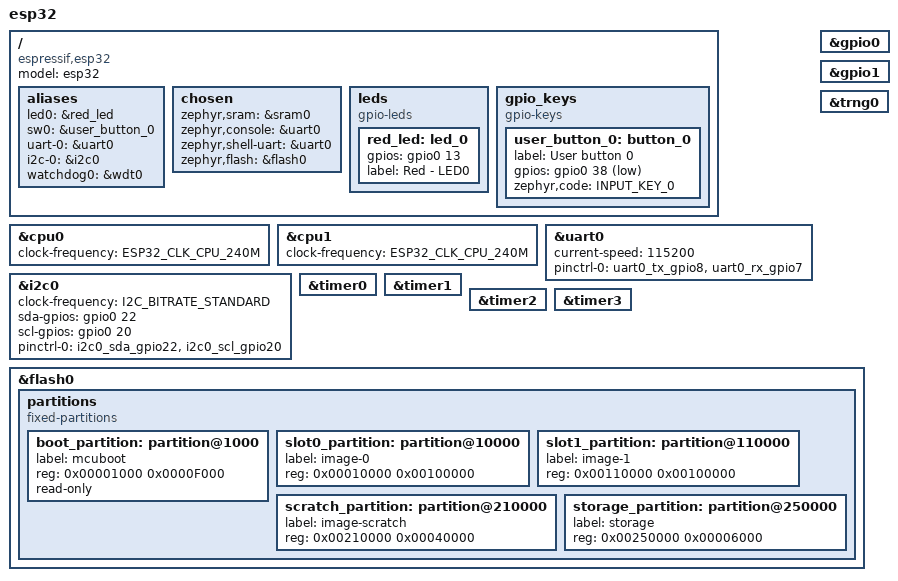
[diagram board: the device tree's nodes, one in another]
/*
 * Copyright (c) 2023 MIT Media Lab
 *
 * SPDX-License-Identifier: Apache-2.0
 */
/dts-v1/;

#include <espressif/esp32/esp32_pico_v3_02.dtsi>
#include "adafruit_feather_esp32_v2-pinctrl.dtsi"
#include <zephyr/dt-bindings/input/input-event-codes.h>

/ {
	model = "esp32";
	compatible = "espressif,esp32";

	aliases {
		led0 = &red_led;
		sw0 = &user_button_0;
		uart-0 = &uart0;
		i2c-0 = &i2c0;
		watchdog0 = &wdt0;
	};

	chosen {
		zephyr,sram = &sram0;
		zephyr,console = &uart0;
		zephyr,shell-uart = &uart0;
		zephyr,flash = &flash0;
	};

	leds {
		compatible = "gpio-leds";

		red_led: led_0 {
			gpios =  <&gpio0 13 GPIO_ACTIVE_HIGH>;
			label = "Red - LED0";
		};
	};

	gpio_keys {
		compatible = "gpio-keys";

		user_button_0: button_0 {
			label = "User button 0";
			gpios = <&gpio0 38 GPIO_ACTIVE_LOW>;
			zephyr,code = <INPUT_KEY_0>;
		};
	};
};

&cpu0 {
	clock-frequency = <ESP32_CLK_CPU_240M>;
};

&cpu1 {
	clock-frequency = <ESP32_CLK_CPU_240M>;
};

&uart0 {
	status = "okay";
	current-speed = <115200>;
	pinctrl-0 = <&uart0_tx_gpio8 &uart0_rx_gpio7>;
	pinctrl-names = "default";
};

&gpio0 {
	status = "okay";
};

&gpio1 {
	status = "okay";
};

&i2c0 {
	status = "okay";
	clock-frequency = <I2C_BITRATE_STANDARD>;
	sda-gpios = <&gpio0 22 GPIO_OPEN_DRAIN>;
	scl-gpios = <&gpio0 20 GPIO_OPEN_DRAIN>;
	pinctrl-0 = <&i2c0_sda_gpio22 &i2c0_scl_gpio20>;
	pinctrl-names = "default";
};

/*
&spi1 {
	#address-cells = <1>;
	#size-cells = <0>;
	status = "okay";
	pinctrl-0 = <&spim2_miso_gpio21 &spim2_mosi_gpio19
				&spim2_sclk_gpio5 &spim2_csel_gpio16>;
	pinctrl-names = "default";
};
*/

&timer0 {
	status = "okay";
};

&timer1 {
	status = "okay";
};

&timer2 {
	status = "okay";
};

&timer3 {
	status = "okay";
};

&trng0 {
	status = "okay";
};

&flash0 {
	status = "okay";
	partitions {
		compatible = "fixed-partitions";
		#address-cells = <1>;
		#size-cells = <1>;

		/* Reserve 60kB for the bootloader */
		boot_partition: partition@1000 {
			label = "mcuboot";
			reg = <0x00001000 0x0000F000>;
			read-only;
		};

		/* Reserve 1024kB for the application in slot 0 */
		slot0_partition: partition@10000 {
			label = "image-0";
			reg = <0x00010000 0x00100000>;
		};

		/* Reserve 1024kB for the application in slot 1 */
		slot1_partition: partition@110000 {
			label = "image-1";
			reg = <0x00110000 0x00100000>;
		};

		/* Reserve 256kB for the scratch partition */
		scratch_partition: partition@210000 {
			label = "image-scratch";
			reg = <0x00210000 0x00040000>;
		};

		storage_partition: partition@250000 {
			label = "storage";
			reg = <0x00250000 0x00006000>;
		};
	};
};
